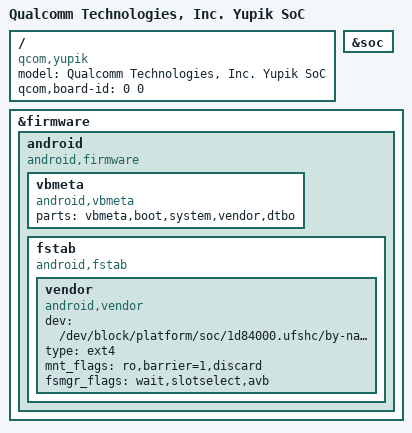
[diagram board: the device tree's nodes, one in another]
// SPDX-License-Identifier: BSD-3-Clause

/dts-v1/;

#include "yupik.dtsi"
#include "yupik-redwood-reserved-memory.dtsi"
#include "yupik-ion.dtsi"

/* Same root as yupik.dts, the board identity comes from the redwood overlay */
/ {
	model = "Qualcomm Technologies, Inc. Yupik SoC";
	compatible = "qcom,yupik";
	qcom,board-id = <0 0>;
};

/* The ION driver serves these heaps, as on the 5.4 base; nothing here reads qcom,dma-heaps */
&soc {
	/delete-node/ qcom,dma-heaps;
};

&firmware {
	android {
		compatible = "android,firmware";
		vbmeta {
			compatible = "android,vbmeta";
			parts = "vbmeta,boot,system,vendor,dtbo";
		};

		fstab {
			compatible = "android,fstab";
			vendor {
				compatible = "android,vendor";
				dev = "/dev/block/platform/soc/1d84000.ufshc/by-name/vendor";

				type = "ext4";
				mnt_flags = "ro,barrier=1,discard";
				fsmgr_flags = "wait,slotselect,avb";
				status = "ok";
			};
		};
	};
};
